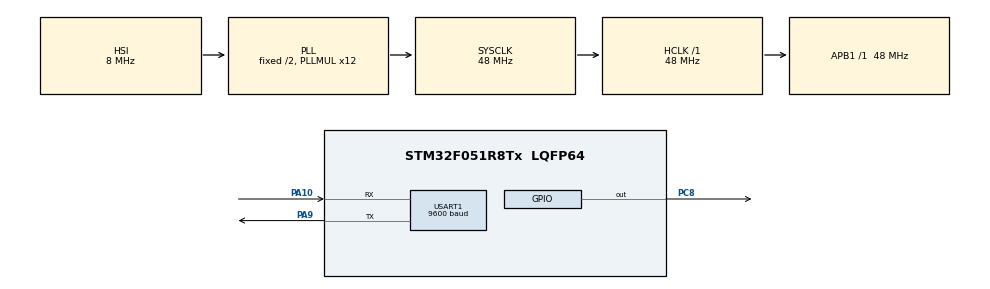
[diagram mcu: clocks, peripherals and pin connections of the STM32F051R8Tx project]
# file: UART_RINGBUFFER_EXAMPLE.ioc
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Mcu.Family=STM32F0
Mcu.Name=STM32F051R8Tx
Mcu.Package=LQFP64
NVIC.USART1_IRQn=true\:0\:0\:false\:false\:true\:true\:true\:true
PA10.Mode=Asynchronous
PA10.Signal=USART1_RX
PA13.Mode=Serial_Wire
PA13.Signal=SYS_SWDIO
PA14.Mode=Serial_Wire
PA14.Signal=SYS_SWCLK
PA9.Mode=Asynchronous
PA9.Signal=USART1_TX
PC8.Signal=GPIO_Output
ProjectManager.HeapSize=0x200
ProjectManager.StackSize=0x400
ProjectManager.TargetToolchain=MDK-ARM V5.32
RCC.AHBFreq_Value=48000000
RCC.APB1Freq_Value=48000000
RCC.APB1TimFreq_Value=48000000
RCC.HCLKFreq_Value=48000000
RCC.PLLMUL=RCC_PLL_MUL12
RCC.SYSCLKFreq_VALUE=48000000
RCC.SYSCLKSource=RCC_SYSCLKSOURCE_PLLCLK
USART1.BaudRate=9600
USART1.VirtualMode-Asynchronous=VM_ASYNC
board=custom

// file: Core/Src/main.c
/* USER CODE BEGIN Header */
/**
  ******************************************************************************
  * @file           : main.c
  * @brief          : Main program body
  ******************************************************************************
  * @attention
  *
  * Copyright (c) 2023 STMicroelectronics.
  * All rights reserved.
  *
  * This software is licensed under terms that can be found in the LICENSE file
  * in the root directory of this software component.
  * If no LICENSE file comes with this software, it is provided AS-IS.
  *
  ******************************************************************************
  */
/* USER CODE END Header */
#include "main.h"

/* USER CODE BEGIN Includes */
#include "ringbuffer.h"
#include <string.h>
/* USER CODE END Includes */

/* USER CODE BEGIN PM */
ring_buffer_t data_buffer; // data buffer
uint8_t recvd_data; // receive buffer
char data_command[20] = {0};
uint8_t start=0; // count how many bytes are received
uint8_t end=0; // count how many bytes are received
/* USER CODE END PM */

UART_HandleTypeDef huart1;

void SystemClock_Config(void);
static void MX_GPIO_Init(void);
static void MX_USART1_UART_Init(void);

/* USER CODE BEGIN 0 */
void HAL_UART_RxCpltCallback(UART_HandleTypeDef *huart)
{
	ring_buffer_put(&data_buffer,recvd_data);

	HAL_UART_Receive_IT(&huart1,&recvd_data,1);
}
void buffer_check(void)
{
	uint8_t c;
	static uint8_t i = 0;

	if(!ring_buffer_is_empty(&data_buffer))
	{
		c = ring_buffer_get(&data_buffer);
		if(0  == start)
		{
			if(c=='*')
			{
				start = 1;
				i = 0;
			}
		} else if(1  == start)
		{
			if(c=='#')
			{
				start = 2;
			}
			else
			{
				data_command[i++]=c;
			}
		}
	}

	if(2  == start)
	{
		//compare and control led
		if(strcmp(data_command,"led on")==0)
		{
			HAL_GPIO_WritePin(GPIOC,GPIO_PIN_8,1);
		}else if(strcmp(data_command,"led off")==0)
		{
			HAL_GPIO_WritePin(GPIOC,GPIO_PIN_8,0);
		}
		memset(data_command,0,20);
		start = 0;
	}

}
/* USER CODE END 0 */

int main(void)
{

  /* MCU Configuration--------------------------------------------------------*/

  /* Reset of all peripherals, Initializes the Flash interface and the Systick. */
  HAL_Init();

  /* Configure the system clock */
  SystemClock_Config();

  /* Initialize all configured peripherals */
  MX_GPIO_Init();
  MX_USART1_UART_Init();
  /* USER CODE BEGIN 2 */
	ring_buffer_init(&data_buffer,64);
	HAL_UART_Receive_IT(&huart1,&recvd_data,1);
  /* USER CODE END 2 */

  /* Infinite loop */
  /* USER CODE BEGIN WHILE */
  while (1)
  {
	buffer_check();
    /* USER CODE END WHILE */

  }
}

void SystemClock_Config(void)
{
  RCC_OscInitTypeDef RCC_OscInitStruct = {0};
  RCC_ClkInitTypeDef RCC_ClkInitStruct = {0};
  RCC_PeriphCLKInitTypeDef PeriphClkInit = {0};

  /** Initializes the RCC Oscillators according to the specified parameters
  * in the RCC_OscInitTypeDef structure.
  */
  RCC_OscInitStruct.OscillatorType = RCC_OSCILLATORTYPE_HSI;
  RCC_OscInitStruct.HSIState = RCC_HSI_ON;
  RCC_OscInitStruct.HSICalibrationValue = RCC_HSICALIBRATION_DEFAULT;
  RCC_OscInitStruct.PLL.PLLState = RCC_PLL_ON;
  RCC_OscInitStruct.PLL.PLLSource = RCC_PLLSOURCE_HSI;
  RCC_OscInitStruct.PLL.PLLMUL = RCC_PLL_MUL12;
  RCC_OscInitStruct.PLL.PREDIV = RCC_PREDIV_DIV1;
  if (HAL_RCC_OscConfig(&RCC_OscInitStruct) != HAL_OK)
  {
    Error_Handler();
  }

  /** Initializes the CPU, AHB and APB buses clocks
  */
  RCC_ClkInitStruct.ClockType = RCC_CLOCKTYPE_HCLK|RCC_CLOCKTYPE_SYSCLK
                              |RCC_CLOCKTYPE_PCLK1;
  RCC_ClkInitStruct.SYSCLKSource = RCC_SYSCLKSOURCE_PLLCLK;
  RCC_ClkInitStruct.AHBCLKDivider = RCC_SYSCLK_DIV1;
  RCC_ClkInitStruct.APB1CLKDivider = RCC_HCLK_DIV1;

  if (HAL_RCC_ClockConfig(&RCC_ClkInitStruct, FLASH_LATENCY_1) != HAL_OK)
  {
    Error_Handler();
  }
  PeriphClkInit.PeriphClockSelection = RCC_PERIPHCLK_USART1;
  PeriphClkInit.Usart1ClockSelection = RCC_USART1CLKSOURCE_PCLK1;
  if (HAL_RCCEx_PeriphCLKConfig(&PeriphClkInit) != HAL_OK)
  {
    Error_Handler();
  }
}

static void MX_USART1_UART_Init(void)
{

  huart1.Instance = USART1;
  huart1.Init.BaudRate = 9600;
  huart1.Init.WordLength = UART_WORDLENGTH_8B;
  huart1.Init.StopBits = UART_STOPBITS_1;
  huart1.Init.Parity = UART_PARITY_NONE;
  huart1.Init.Mode = UART_MODE_TX_RX;
  huart1.Init.HwFlowCtl = UART_HWCONTROL_NONE;
  huart1.Init.OverSampling = UART_OVERSAMPLING_16;
  huart1.Init.OneBitSampling = UART_ONE_BIT_SAMPLE_DISABLE;
  huart1.AdvancedInit.AdvFeatureInit = UART_ADVFEATURE_NO_INIT;
  if (HAL_UART_Init(&huart1) != HAL_OK)
  {
    Error_Handler();
  }

}

static void MX_GPIO_Init(void)
{
  GPIO_InitTypeDef GPIO_InitStruct = {0};

  /* GPIO Ports Clock Enable */
  __HAL_RCC_GPIOC_CLK_ENABLE();
  __HAL_RCC_GPIOA_CLK_ENABLE();

  /*Configure GPIO pin Output Level */
  HAL_GPIO_WritePin(GPIOC, GPIO_PIN_8, GPIO_PIN_RESET);

  /*Configure GPIO pin : PC8 */
  GPIO_InitStruct.Pin = GPIO_PIN_8;
  GPIO_InitStruct.Mode = GPIO_MODE_OUTPUT_PP;
  GPIO_InitStruct.Pull = GPIO_NOPULL;
  GPIO_InitStruct.Speed = GPIO_SPEED_FREQ_LOW;
  HAL_GPIO_Init(GPIOC, &GPIO_InitStruct);

}

void Error_Handler(void)
{
  __disable_irq();
  while (1)
  {
  }
}
